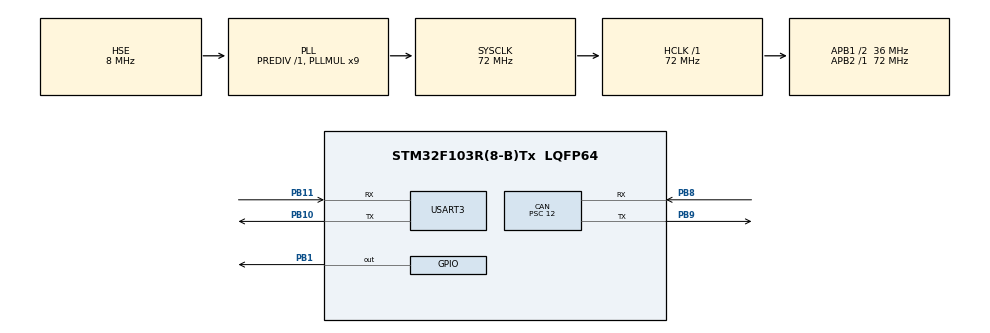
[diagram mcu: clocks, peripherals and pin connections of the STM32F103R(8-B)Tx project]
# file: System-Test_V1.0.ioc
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CAN.BS1=CAN_BS1_3TQ
CAN.BS2=CAN_BS2_2TQ
CAN.CalculateTimeBit=2000
CAN.CalculateTimeQuantum=333.33333333333337
CAN.Prescaler=12
Mcu.Family=STM32F1
Mcu.Name=STM32F103R(8-B)Tx
Mcu.Package=LQFP64
NVIC.PriorityGroup=NVIC_PRIORITYGROUP_4
NVIC.TIM1_UP_IRQn=true\:0\:0\:false\:false\:true\:true\:true
NVIC.USB_LP_CAN1_RX0_IRQn=true\:0\:0\:false\:false\:true\:true\:true
PA13.Mode=Serial_Wire
PA13.Signal=SYS_JTMS-SWDIO
PA14.Mode=Serial_Wire
PA14.Signal=SYS_JTCK-SWCLK
PB1.Signal=GPIO_Output
PB10.Mode=Asynchronous
PB10.Signal=USART3_TX
PB11.Mode=Asynchronous
PB11.Signal=USART3_RX
PB8.Mode=Master
PB8.Signal=CAN_RX
PB9.Mode=Master
PB9.Signal=CAN_TX
PD0-OSC_IN.Mode=HSE-External-Oscillator
PD0-OSC_IN.Signal=RCC_OSC_IN
PD1-OSC_OUT.Mode=HSE-External-Oscillator
PD1-OSC_OUT.Signal=RCC_OSC_OUT
ProjectManager.HeapSize=0x200
ProjectManager.StackSize=0x400
ProjectManager.TargetToolchain=MDK-ARM V5.27
RCC.AHBFreq_Value=72000000
RCC.APB1CLKDivider=RCC_HCLK_DIV2
RCC.APB1Freq_Value=36000000
RCC.APB1TimFreq_Value=72000000
RCC.APB2Freq_Value=72000000
RCC.APB2TimFreq_Value=72000000
RCC.EnbaleCSS=true
RCC.HCLKFreq_Value=72000000
RCC.PLLMUL=RCC_PLL_MUL9
RCC.PLLSourceVirtual=RCC_PLLSOURCE_HSE
RCC.SYSCLKFreq_VALUE=72000000
RCC.SYSCLKSource=RCC_SYSCLKSOURCE_PLLCLK
RCC.USBFreq_Value=72000000
TIM1.AutoReloadPreload=TIM_AUTORELOAD_PRELOAD_ENABLE
TIM1.Period=1000-1
TIM1.Prescaler=36000-1
USART3.VirtualMode=VM_ASYNC
VP_TIM1_VS_ClockSourceINT.Mode=Internal
board=custom

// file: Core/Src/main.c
/* USER CODE BEGIN Header */
/**
  ******************************************************************************
  * @file           : main.c
  * @brief          : Main program body
  ******************************************************************************
  * @attention
  *
  * <h2><center>&copy; Copyright (c) 2020 STMicroelectronics.
  * All rights reserved.</center></h2>
  *
  * This software component is licensed by ST under BSD 3-Clause license,
  * the "License"; You may not use this file except in compliance with the
  * License. You may obtain a copy of the License at:
  *                        opensource.org/licenses/BSD-3-Clause
  *
  ******************************************************************************
  */
/* USER CODE END Header */
#include "main.h"
#include "can.h"
#include "tim.h"
#include "usart.h"
#include "gpio.h"

void SystemClock_Config(void);

int main(void)
{

  /* MCU Configuration--------------------------------------------------------*/

  /* Reset of all peripherals, Initializes the Flash interface and the Systick. */
  HAL_Init();

  /* Configure the system clock */
  SystemClock_Config();

  /* Initialize all configured peripherals */
  MX_GPIO_Init();
  MX_CAN_Init();
  MX_USART3_UART_Init();
  MX_TIM1_Init();
  /* USER CODE BEGIN 2 */

	CAN_Init();//CAN初始化

  /* USER CODE END 2 */

  /* Infinite loop */
  while (1)
  {

    /* USER CODE BEGIN 3 */

		ZLAC8015D_Test();//ZLAC8015D控制

  }
  /* USER CODE END 3 */
}

void SystemClock_Config(void)
{
  RCC_OscInitTypeDef RCC_OscInitStruct = {0};
  RCC_ClkInitTypeDef RCC_ClkInitStruct = {0};

  /** Initializes the RCC Oscillators according to the specified parameters
  * in the RCC_OscInitTypeDef structure.
  */
  RCC_OscInitStruct.OscillatorType = RCC_OSCILLATORTYPE_HSE;
  RCC_OscInitStruct.HSEState = RCC_HSE_ON;
  RCC_OscInitStruct.HSEPredivValue = RCC_HSE_PREDIV_DIV1;
  RCC_OscInitStruct.HSIState = RCC_HSI_ON;
  RCC_OscInitStruct.PLL.PLLState = RCC_PLL_ON;
  RCC_OscInitStruct.PLL.PLLSource = RCC_PLLSOURCE_HSE;
  RCC_OscInitStruct.PLL.PLLMUL = RCC_PLL_MUL9;
  if (HAL_RCC_OscConfig(&RCC_OscInitStruct) != HAL_OK)
  {
    Error_Handler();
  }
  /** Initializes the CPU, AHB and APB buses clocks
  */
  RCC_ClkInitStruct.ClockType = RCC_CLOCKTYPE_HCLK|RCC_CLOCKTYPE_SYSCLK
                              |RCC_CLOCKTYPE_PCLK1|RCC_CLOCKTYPE_PCLK2;
  RCC_ClkInitStruct.SYSCLKSource = RCC_SYSCLKSOURCE_PLLCLK;
  RCC_ClkInitStruct.AHBCLKDivider = RCC_SYSCLK_DIV1;
  RCC_ClkInitStruct.APB1CLKDivider = RCC_HCLK_DIV2;
  RCC_ClkInitStruct.APB2CLKDivider = RCC_HCLK_DIV1;

  if (HAL_RCC_ClockConfig(&RCC_ClkInitStruct, FLASH_LATENCY_2) != HAL_OK)
  {
    Error_Handler();
  }
  /** Enables the Clock Security System
  */
  HAL_RCC_EnableCSS();
}

void Error_Handler(void)
{
}

/************************ (C) COPYRIGHT STMicroelectronics *****END OF FILE****/
